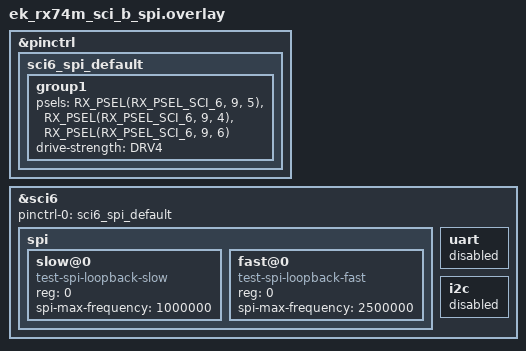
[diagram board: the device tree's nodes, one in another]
/*
 * Copyright (c) 2026 Renesas Electronics Corporation
 * SPDX-License-Identifier: Apache-2.0
 */

&pinctrl {
	sci6_spi_default: sci6_spi_default {
		group1 {
			/* MISO MOSI SCK */
			psels = <RX_PSEL(RX_PSEL_SCI_6, 9, 5)>,
				<RX_PSEL(RX_PSEL_SCI_6, 9, 4)>,
				<RX_PSEL(RX_PSEL_SCI_6, 9, 6)>;
			drive-strength = "DRV4";
		};
	};
};

&sci6 {
	pinctrl-0 = <&sci6_spi_default>;
	pinctrl-names = "default";
	status = "okay";

	spi {
		status = "okay";
		slow@0 {
			compatible = "test-spi-loopback-slow";
			reg = <0>;
			spi-max-frequency = <1000000>;
		};

		fast@0 {
			compatible = "test-spi-loopback-fast";
			reg = <0>;
			spi-max-frequency = <2500000>;
		};
	};

	uart {
		status = "disabled";
	};

	i2c {
		status = "disabled";
	};
};
